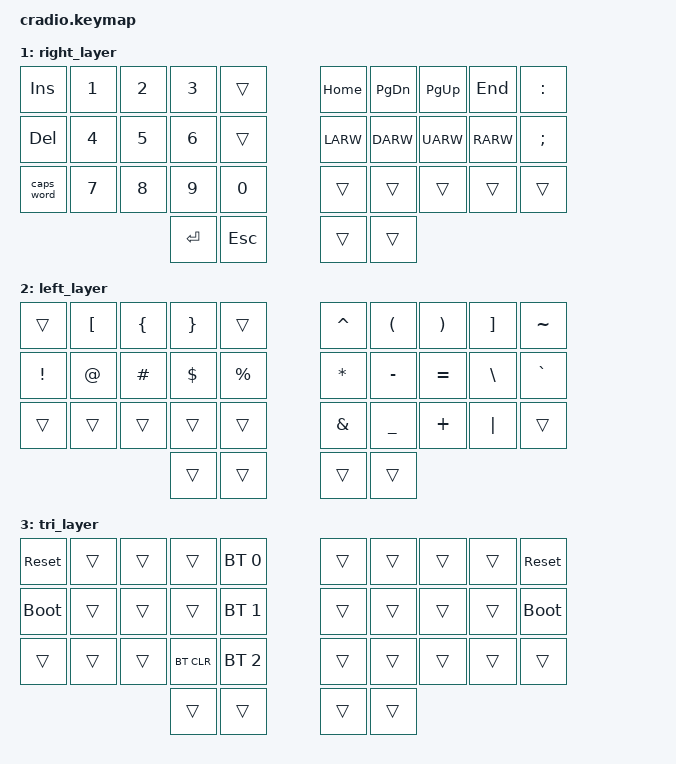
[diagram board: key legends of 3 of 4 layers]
// Copyright (c) 2022 The ZMK Contributors
// SPDX-License-Identifier: MIT

#include <behaviors.dtsi>
#include <dt-bindings/zmk/keys.h>
#include <dt-bindings/zmk/bt.h>

// Home row mods macro
#define HRML(k1,k2,k3,k4) &ht LSHFT k1  &ht LALT k2  &ht LCTRL k3  &ht LGUI k4
#define HRMR(k1,k2,k3,k4) &ht RGUI k1  &ht RCTRL k2  &ht RALT k3  &ht RSHFT k4

/ {
   behaviors {
        ht: hold_tap {
            label = "hold_tap";
            compatible = "zmk,behavior-hold-tap";
            #binding-cells = <2>;
            flavor = "tap-preferred";
            tapping-term-ms = <220>;
            quick-tap-ms = <150>;
            global-quick-tap;
            bindings = <&kp>, <&kp>;
        };
        td0: tap_dance_0 {
            compatible = "zmk,behavior-tap-dance";
            label = "TAP_DANCE_0";
            #binding-cells = <0>;
            tapping-term-ms = <200>;
            bindings = <&kp N1>, <&kp N2>, <&kp N3>;
        };
    };

    conditional_layers {
        compatible = "zmk,conditional-layers";
        tri_layer {
            if-layers = <1 2>;
            then-layer = <3>;
        };
    };

    keymap {
        compatible = "zmk,keymap";
        default_layer {
            bindings = <
        //╭──────────┬──────────┬──────────┬──────────┬──────────╮   ╭──────────┬──────────┬──────────┬──────────┬──────────╮
        //│  Q       │  W       │  F       │  P       │  B       │   │  J       │  L       │  U       │  Y       │  SQT     │
            &kp Q      &kp W      &kp F      &kp P      &kp B          &kp J      &kp L      &kp U      &kp Y      &kp SQT
        //├──────────┼──────────┼──────────┼──────────┼──────────┤   ├──────────┼──────────┼──────────┼──────────┼──────────┤
        //│  A       │  R       │  S       │  T       │  G       │   │  M       │  N       │  E       │  I       │ O        │
            HRML(A,        R,         S,         T)     &kp G          &kp M      HRMR(N,       E,         I,        O)
        //├──────────┼──────────┼──────────┼──────────┼──────────┤   ├──────────┼──────────┼──────────┼──────────┼──────────┤
        //│  Z       │  X       │  C       │  D       │  V       │   │  K       │  H       │ , <      │ . >      │ / ?      │
            &kp Z      &kp X      &kp C      &kp D      &kp V          &kp K      &kp H      &kp COMMA  &kp DOT    &kp FSLH
        //╰──────────┴──────────┴──────────┼──────────┼──────────┤   ├──────────┼──────────┼──────────┴──────────┴──────────╯
                                            &lt 2 TAB   &td0          &kp SPACE  &lt 1 BSPC
        //                                 ╰──────────┴──────────╯   ╰──────────┴──────────╯
            >;
        };

        right_layer {
            bindings = <
        //╭──────────┬──────────┬──────────┬──────────┬──────────╮   ╭──────────┬──────────┬──────────┬──────────┬──────────╮
        //│ INSERT   │  1       │  2       │  3       │          │   │ HOME     │ PAGE DN  │ PAGE UP  │ END      │  :       │
            &kp INS    &kp N1     &kp N2     &kp N3     &trans         &kp HOME   &kp PG_DN  &kp PG_UP  &kp END    &kp COLON
        //├──────────┼──────────┼──────────┼──────────┼──────────┤   ├──────────┼──────────┼──────────┼──────────┼──────────┤
        //│ DELETE   │  4       │  5       │  6       │          │   │ LEFT     │ DOWN     │ UP       │ RIGHT    │  ;       │
            &kp DEL    &kp N4     &kp N5     &kp N6     &trans         &kp LARW   &kp DARW   &kp UARW   &kp RARW   &kp SEMI
        //├──────────┼──────────┼──────────┼──────────┼──────────┤   ├──────────┼──────────┼──────────┼──────────┼──────────┤
        //│ CAPS     │  7       │  8       │  9       │  0       │   │          │          │          │          │          │
           &caps_word  &kp N7     &kp N8     &kp N9     &kp N0         &trans     &trans     &trans     &trans     &trans
        //╰──────────┴──────────┴──────────┼──────────┼──────────┤   ├──────────┼──────────┼──────────┴──────────┴──────────╯
                                             &kp ENTER     &kp ESC        &trans     &trans
        //                                 ╰──────────┴──────────╯   ╰──────────┴──────────╯
            >;
        };

        left_layer {
            bindings = <
        //╭──────────┬──────────┬──────────┬──────────┬──────────╮   ╭──────────┬──────────┬──────────┬──────────┬──────────╮
        //│          │  [       │  {       │  }       │          │   │  ^       │  (       │  )       │  ]       │  ~       │
            &trans     &kp LBKT   &kp LBRC   &kp RBRC   &trans         &kp CARET  &kp LPAR   &kp RPAR   &kp RBKT   &kp TILDE
        //├──────────┼──────────┼──────────┼──────────┼──────────┤   ├──────────┼──────────┼──────────┼──────────┼──────────┤
        //│  !       │  @       │  #       │  $       │  %       │   │  *       │  -       │  =       │  \       │  `       │
            &kp EXCL   &kp AT     &kp HASH   &kp DLLR   &kp PRCNT      &kp ASTRK  &kp MINUS  &kp EQUAL  &kp BSLH   &kp GRAVE
        //├──────────┼──────────┼──────────┼──────────┼──────────┤   ├──────────┼──────────┼──────────┼──────────┼──────────┤
        //│          │          │          │          │          │   │  &       │  _       │  +       │  │       │          │
            &trans     &trans     &trans     &trans     &trans         &kp AMPS   &kp UNDER  &kp PLUS   &kp PIPE   &trans
        //╰──────────┴──────────┴──────────┼──────────┼──────────┤   ├──────────┼──────────┼──────────┴──────────┴──────────╯
                                             &trans     &trans         &trans     &trans
        //                                 ╰──────────┴──────────╯   ╰──────────┴──────────╯
            >;
        };

        tri_layer {
            bindings = <
        //╭──────────┬──────────┬──────────┬──────────┬──────────╮   ╭──────────┬──────────┬──────────┬──────────┬──────────╮
        //│ RESET    │          │          │          │PROFILE 0 │   │          │          │          │          │  RESET   │
           &sys_reset  &trans     &trans     &trans    &bt BT_SEL 0    &trans     &trans     &trans     &trans    &sys_reset
        //├──────────┼──────────┼──────────┼──────────┼──────────┤   ├──────────┼──────────┼──────────┼──────────┼──────────┤
        //│BOOTLOADER│          │          │          │PROFILE 1 │   │          │          │          │          │BOOTLOADER│
          &bootloader  &trans     &trans     &trans    &bt BT_SEL 1    &trans     &trans     &trans     &trans    &bootloader
        //├──────────┼──────────┼──────────┼──────────┼──────────┤   ├──────────┼──────────┼──────────┼──────────┼──────────┤
        //│          │          │          │ CLEAR BT │PROFILE 2 │   │          │          │          │          │          │
            &trans     &trans     &trans    &bt BT_CLR &bt BT_SEL 2    &trans     &trans     &trans     &trans     &trans
        //╰──────────┴──────────┴──────────┼──────────┼──────────┤   ├──────────┼──────────┼──────────┴──────────┴──────────╯
                                             &trans     &trans         &trans     &trans
        //                                 ╰──────────┴──────────╯   ╰──────────┴──────────╯
            >;
        };
    };
};
